# AE402FA0E5597BE0_CM55_HE_View register map
Vendor: Alif Semiconductor; Series: E4; File version: 1.0
CPU: CM55 r1p0, selectable endian, MPU, FPU, double-precision FPU, DSP, VTOR, 8 interrupt priority bits, 1 SAU regions
Registers are 32-bit, read-write, reset 0x0 unless marked. A register's access mark holds for its fields unless they carry their own. Offsets are from the block's base; [hi:lo] are bit positions; {n}, {i} and the like mark numbered series.

## IRQRTR
Base 0x1A500000
0x00 IRQRTR_CTRL — IRQRTR Control Register
  [0] ERR — Configures the response for configuration accesses which generate a configuration access error:
    0=No error; 1=Error
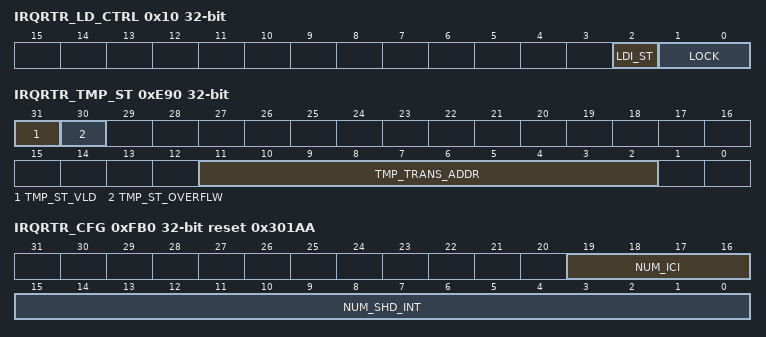
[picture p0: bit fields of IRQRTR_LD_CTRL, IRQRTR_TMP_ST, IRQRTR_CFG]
0x10 IRQRTR_LD_CTRL (reset mask 0xFFFFFFFB) — IRQRTR Lockdown Control Register
  [2] LDI_ST ro — Indicates the current status of the lockdown interface: NOTE: Depends on the value of the [INT_RTR_LOCK] bit in the system lock control registers {SYS_LCTRL_ST, SYS_LCTRL_SET, SYS_LCTRL_CLR}.
    0=Lockdown interface is de-asserted; 1=Lockdown interface is asserted
  [1:0] LOCK — Indicates the lock state of the IRQRTR:
    0=Open lockdown state; 2=Partial lockdown state; 3=Full lockdown state
0x100 IRQRTR_SHD_INT_INFO ro (reset mask 0xFFFFFFF0) — IRQRTR Shared Interrupt Information Register
  [3:0] ICI_DST — Interrupt Controller Destination. Each bit indicates whether the interrupt selected by the IRQRTR_SHD_INT_SEL[INT_SEL] field canbe routed to the ICI interface associated with the bit, starting with bit 0 for ICI0 to bit 3 for ICI3:
    0=Shared interrupt cannot be routed to the ICI[n]; 1=Shared interrupt can be routed to the ICI[n]
0x104 IRQRTR_SHD_INT_CFG (reset mask 0xFFFFFFF0) — IRQRTR Shared Interrupt Configuration Register
  [3:0] ICI_EN — Interrupt Controller Enable. Each bit indicates whether the interrupt selected by the IRQRTR_SHD_INT_SEL[INT_SEL] field isrouted to the ICI interface associated with the bit, starting with bit 0 for ICI0 to bit 3 for ICI3: Note: Bits where the respective bit in the IRQRTR_SHD_INT_INFO[ICI_DST] field is 0x0 are reserved andtreated as RAZ/WI.
    0=Shared interrupt is not routed to the ICI[n]; 1=Shared interrupt is routed to the ICI[n]
0x108 IRQRTR_SHD_INT_LCTRL — IRQRTR Shared Interrupt Lock Control Register
  [31] LOCK — Controls the lock status of the interrupt selected by the IRQRTR_SHD_INT_SEL[INT_SEL] field: This field becomes read-only when this field is set to 0x1 and the IRQRTR_LD_CTRL[LOCK] field isset to 0x2 (partial lockdown) or 0x3 (full lockdown).
    0=Shared interrupt is not locked; 1=Shared interrupt is locked
0x10C IRQRTR_SHD_INT_SEL — IRQRTR Shared Interrupt Select Register
  [15:0] INT_SEL — Selects which interrupt the IRQRTR_SHD_INT_INFO, IRQRTR_SHD_INT_CFG and IRQRTR_SHD_INT_LCTRL registersrefer to. When the value in this field is greater than the value in the IRQRTR_CFG[NUM_SHD_INT] field, the fields in IRQRTR_SHD_INT_INFO,IRQRTR_SHD_INT_CFG and IRQRTR_SHD_INT_LCTRL are reserved and treated as RAZ/WI.
0xE90 IRQRTR_TMP_ST (reset mask 0xFFFFF003) — IRQRTR Tamper Status Register
  [31] TMP_ST_VLD write-1-clears — Indicates whether the IRQRTR_TMP_ST register contains valid data or not. This field is 'write-1-to-clear'. Writing 0 has no effect.
    0=IRQRTR_TMP_ST does not contain valid data; 1=IRQRTR_TMP_ST contains valid data
  [30] TMP_ST_OVERFLW write-1-clears — Indicates whether a tamper transaction occurred, while the IRQRTR_TMP_ST[TMP_ST_VLD] was 0x1: This field is 'write-1-to-clear'. Writing 0 has no effect.
    0=No tamper transaction overflow occurred; 1=Tamper transaction overflow occurred
  [11:2] TMP_TRANS_ADDR ro — Address of the register accessed by the tamper transaction. When TMP_ST_VLD is 0, this field is not valid.
0xFA0 IRQRTR_CAP ro reset 0x2 — IRQRTR Capability Register
  [3:0] LDE_LVL — Level of the Lockdown Extension implemented by the IRQRTR.
    2=LDE.2 (open, partial and full lockdown support)
0xFB0 IRQRTR_CFG ro reset 0x301AA — IRQRTR Configuration Register
  [19:16] NUM_ICI — Number of ICIs supported by the IRQRTR:
    3=4 ICIs
  [15:0] NUM_SHD_INT — Number of shared interrupts supported by the IRQRTR:
    0x1AA=427 shared interrupts
